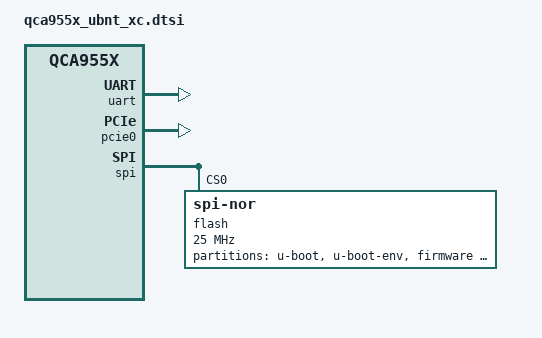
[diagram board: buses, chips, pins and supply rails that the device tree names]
// SPDX-License-Identifier: GPL-2.0

#include <dt-bindings/gpio/gpio.h>
#include <dt-bindings/input/input.h>

#include "qca955x.dtsi"

&uart {
	status = "okay";
};

&pcie0 {
	status = "okay";
};

&spi {
	status = "okay";
	num-cs = <1>;

	flash@0 {
		compatible = "jedec,spi-nor";
		reg = <0>;
		spi-max-frequency = <25000000>;

		partitions {
			compatible = "fixed-partitions";
			#address-cells = <1>;
			#size-cells = <1>;

			partition@0 {
				label = "u-boot";
				reg = <0x000000 0x040000>;
				read-only;
			};

			partition@40000 {
				label = "u-boot-env";
				reg = <0x040000 0x010000>;
				read-only;
			};

			partition@50000 {
				compatible = "denx,uimage";
				label = "firmware";
				reg = <0x050000 0xf60000>;
			};

			partition@fb0000 {
				label = "cfg";
				reg = <0xfb0000 0x040000>;
				read-only;
			};

			art: partition@ff0000 {
				label = "art";
				reg = <0xff0000 0x010000>;
				read-only;
			};
		};
	};
};
